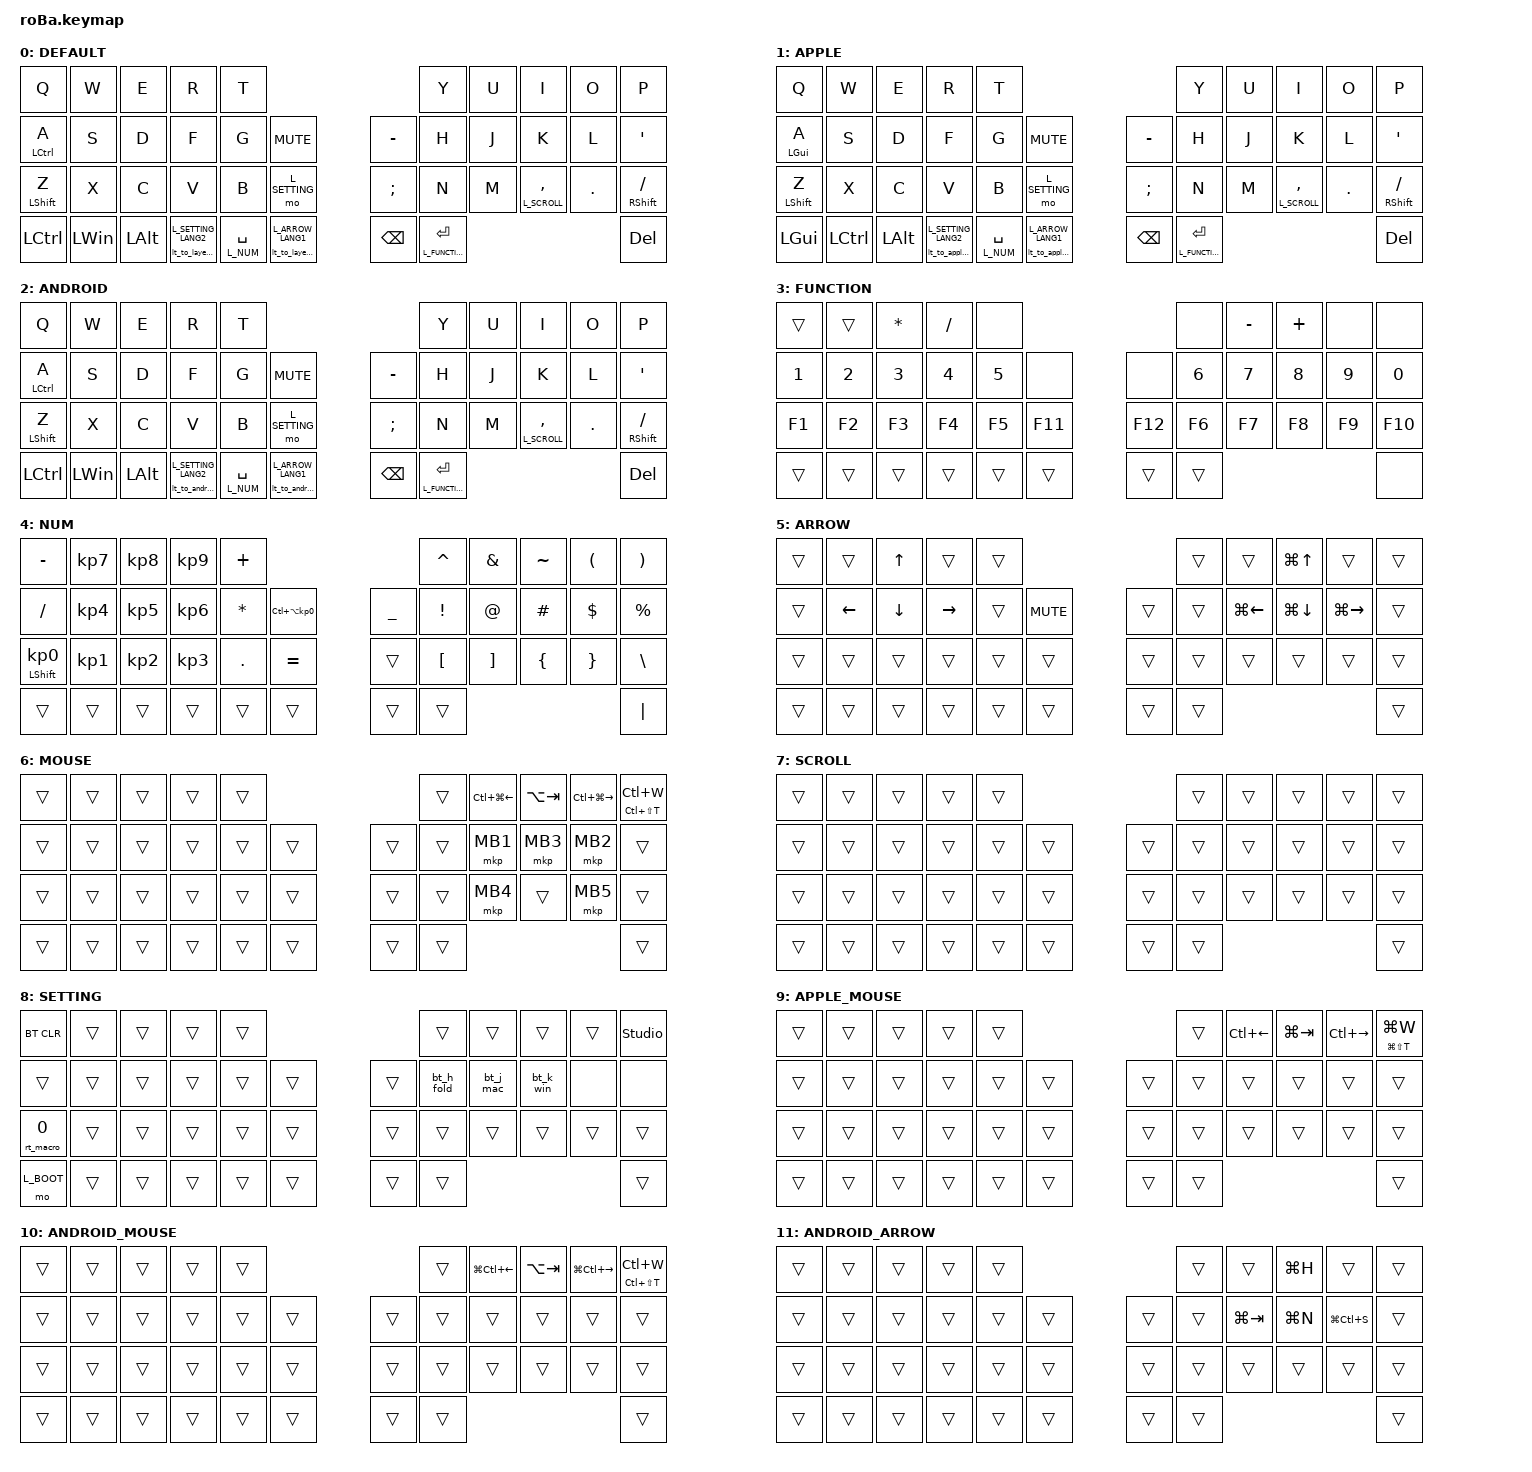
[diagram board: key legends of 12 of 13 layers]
#include <behaviors.dtsi>
#include <dt-bindings/zmk/bt.h>
#include <dt-bindings/zmk/keys.h>
#include <dt-bindings/zmk/pointing.h>
#include <behaviors/runtime-sensor-rotate.dtsi>

#undef ZMK_POINTING_DEFAULT_SCRL_VAL

#define ZMK_POINTING_DEFAULT_SCRL_VAL 80

// Base layers (DEFAULT/APPLE/ANDROID) MUST stay at the lowest indices: ZMK
// resolves a key from the highest active layer, so a base layer numbered
// above SETTING/MOUSE/etc. shadows every momentary layer (bug seen 2026-09-07).
#define L_DEFAULT       0
#define L_APPLE         1
#define L_ANDROID       2
#define L_FUNCTION      3
#define L_NUM           4
#define L_ARROW         5
#define L_MOUSE         6
#define L_SCROLL        7
#define L_SETTING       8
#define L_APPLEMOUSE    9
#define L_ANDROID_MOUSE 10
#define L_ANDROID_ARROW 11
#define L_BOOT          12   // momentary-only; &bootloader chords, everything else &none

&mt {
    flavor = "balanced";
    quick-tap-ms = <0>;
};

&trackball {
    automouse-layer = <L_MOUSE>;
    scroll-layers = <L_SCROLL>;

    // arrows {
    //     layers = <3>;
    //     bindings =
    //         <&kp RIGHT_ARROW>,
    //         <&kp LEFT_ARROW>,
    //         <&kp UP_ARROW>,
    //         <&kp DOWN_ARROW>;
    //     tick = <10>;
    //     wait-ms = <5>;
    //     tap-ms = <5>;
    // };
};

/ {
    combos {
        compatible = "zmk,runtime-combos";

        tab {
            bindings = <&kp TAB>;
            key-positions = <11 10>;
        };

        esc {
            bindings = <&kp ESCAPE>;
            key-positions = <0 1>;
        };

        backspace {
            bindings = <&kp BACKSPACE>;
            key-positions = <9 8>;
        };

        delete {
            bindings = <&kp DELETE>;
            key-positions = <20 21>;
        };

        redo_win {
            bindings = <&kp LC(LS(Z))>;
            key-positions = <22 23 24>;
            layers = <L_DEFAULT L_MOUSE L_ANDROID L_ANDROID_MOUSE>;
        };

        redo_apple {
            bindings = <&kp LG(LS(Z))>;
            key-positions = <22 23 24>;
            layers = <L_APPLE L_APPLEMOUSE>;
        };

        // ; + Del + P (all right hand, 3 keys at once) = UF2 bootloader on the
        // RIGHT half. Combos run on the central (right), which is what we want.
        // Left-half bootloader is the layer chord SETTING + Ctrl + Q (see BOOT).
        bootloader_right {
            bindings = <&bootloader>;
            key-positions = <28 42 9>;
        };
    };

    macros {
        to_layer_0: to_layer_0 {
            compatible = "zmk,behavior-macro-one-param";
            #binding-cells = <1>;
            bindings = <&to L_DEFAULT &macro_param_1to1 &kp MACRO_PLACEHOLDER>;
            label = "TO_LAYER_0";
        };

        to_apple_default: to_apple_default {
            compatible = "zmk,behavior-macro-one-param";
            #binding-cells = <1>;
            bindings = <&to L_APPLE &macro_param_1to1 &kp MACRO_PLACEHOLDER>;
            label = "TO_APPLE_DEFAULT";
        };

        to_android: to_android {
            compatible = "zmk,behavior-macro-one-param";
            #binding-cells = <1>;
            bindings = <&to L_ANDROID &macro_param_1to1 &kp MACRO_PLACEHOLDER>;
            label = "TO_ANDROID";
        };

        // BT profile -> base-layer routing (SETTING layer, right home row).
        // H = Galaxy Z Fold 8 (profile 3, kept from the former SQT slot so the
        // existing bond survives), J = Mac mini (0), K = office Windows (1).
        // L / SQT are intentionally empty (&none). Profiles 2/4 are unused.
        bt_h_fold: bt_h_fold {
            compatible = "zmk,behavior-macro";
            #binding-cells = <0>;
            bindings = <&bt BT_SEL 3 &to L_ANDROID>;
            label = "BT_H_FOLD";
        };

        bt_j_mac: bt_j_mac {
            compatible = "zmk,behavior-macro";
            #binding-cells = <0>;
            bindings = <&bt BT_SEL 0 &to L_APPLE>;
            label = "BT_J_MAC";
        };

        bt_k_win: bt_k_win {
            compatible = "zmk,behavior-macro";
            #binding-cells = <0>;
            bindings = <&bt BT_SEL 1 &to L_DEFAULT>;
            label = "BT_K_WIN";
        };
    };

    behaviors {
        rt_macro: rt_macro {
            compatible = "zmk,behavior-runtime-macro";
            #binding-cells = <1>;
        };

        lt_to_layer_0: lt_to_layer_0 {
            compatible = "zmk,behavior-runtime-hold-tap";
            label = "LAYER_TAP_TO_0";
            bindings = <&mo>, <&to_layer_0>;

            #binding-cells = <2>;
            tapping-term-ms = <200>;
        };

        lt_to_apple_default: lt_to_apple_default {
            compatible = "zmk,behavior-runtime-hold-tap";
            label = "LAYER_TAP_TO_APPLE";
            bindings = <&mo>, <&to_apple_default>;

            #binding-cells = <2>;
            tapping-term-ms = <200>;
        };

        lt_to_android: lt_to_android {
            compatible = "zmk,behavior-runtime-hold-tap";
            label = "LAYER_TAP_TO_ANDROID";
            bindings = <&mo>, <&to_android>;

            #binding-cells = <2>;
            tapping-term-ms = <200>;
        };

        encoder_msc_down_up: encoder_msc_down_up {
            compatible = "zmk,behavior-sensor-rotate";
            label = "ENCODER_MSC_DOWN_UP";
            #sensor-binding-cells = <0>;
            bindings = <&msc SCRL_UP>, <&msc SCRL_DOWN>;

            tap-ms = <50>;
        };

        encoder_vol_down_up: encoder_vol_down_up {
            compatible = "zmk,behavior-runtime-sensor-rotate";
            label = "ENCODER_VOL_DOWN_UP";
            #sensor-binding-cells = <0>;
            cw-binding = <&kp C_VOLUME_DOWN>;
            ccw-binding = <&kp C_VOLUME_UP>;

            tap-ms = <20>;
        };
    };

    conditional_layers {
        compatible = "zmk,runtime-conditional-layers";

        apple_mouse {
            if-layers = <L_APPLE L_MOUSE>;
            then-layer = <L_APPLEMOUSE>;
        };

        android_mouse {
            if-layers = <L_ANDROID L_MOUSE>;
            then-layer = <L_ANDROID_MOUSE>;
        };

        android_arrow {
            if-layers = <L_ANDROID L_ARROW>;
            then-layer = <L_ANDROID_ARROW>;
        };
    };

    keymap {
        compatible = "zmk,keymap";

        DEFAULT {
            bindings = <
&kp Q               &kp W         &kp E         &kp R                        &kp T                                                            &kp Y        &kp U  &kp I               &kp O    &kp P
&mt LEFT_CONTROL A  &kp S         &kp D         &kp F                        &kp G        &kp K_MUTE                           &kp MINUS      &kp H        &kp J  &kp K               &kp L    &kp SQT
&mt LEFT_SHIFT Z    &kp X         &kp C         &kp V                        &kp B        &mo L_SETTING                        &kp SEMICOLON  &kp N        &kp M  &lt L_SCROLL COMMA  &kp DOT  &mt RIGHT_SHIFT SLASH
&kp LCTRL           &kp LEFT_WIN  &kp LEFT_ALT  &lt_to_layer_0 L_SETTING LANG2  &lt L_NUM SPACE  &lt_to_layer_0 L_ARROW LANG1      &kp BACKSPACE  &lt L_FUNCTION ENTER                               &kp DEL
            >;

            sensor-bindings = <&encoder_vol_down_up>;
        };

        APPLE {
            bindings = <
&kp Q             &kp W         &kp E         &kp R                                 &kp T                                                                     &kp Y        &kp U  &kp I               &kp O    &kp P
&mt LEFT_GUI A    &kp S         &kp D         &kp F                                 &kp G        &kp K_MUTE                                    &kp MINUS      &kp H        &kp J  &kp K               &kp L    &kp SQT
&mt LEFT_SHIFT Z  &kp X         &kp C         &kp V                                 &kp B        &mo L_SETTING                                 &kp SEMICOLON  &kp N        &kp M  &lt L_SCROLL COMMA  &kp DOT  &mt RIGHT_SHIFT SLASH
&kp LEFT_GUI      &kp LCTRL     &kp LEFT_ALT  &lt_to_apple_default L_SETTING LANG2  &lt L_NUM SPACE  &lt_to_apple_default L_ARROW LANG1      &kp BACKSPACE  &lt L_FUNCTION ENTER                               &kp DEL
            >;

            sensor-bindings = <&encoder_vol_down_up>;
        };

        // Android (Galaxy Z Fold 8). Meta = LEFT_GUI. Same Ctrl-based base as
        // DEFAULT(Win); only the hold-tap &to target differs so the
        // conditional layers below can key off L_ANDROID.
        ANDROID {
            bindings = <
&kp Q               &kp W         &kp E         &kp R                           &kp T                                                               &kp Y        &kp U  &kp I               &kp O    &kp P
&mt LEFT_CONTROL A  &kp S         &kp D         &kp F                           &kp G        &kp K_MUTE                              &kp MINUS      &kp H        &kp J  &kp K               &kp L    &kp SQT
&mt LEFT_SHIFT Z    &kp X         &kp C         &kp V                           &kp B        &mo L_SETTING                           &kp SEMICOLON  &kp N        &kp M  &lt L_SCROLL COMMA  &kp DOT  &mt RIGHT_SHIFT SLASH
&kp LCTRL           &kp LEFT_WIN  &kp LEFT_ALT  &lt_to_android L_SETTING LANG2  &lt L_NUM SPACE  &lt_to_android L_ARROW LANG1      &kp BACKSPACE  &lt L_FUNCTION ENTER                               &kp DEL
            >;

            sensor-bindings = <&encoder_vol_down_up>;
        };

        FUNCTION {
            bindings = <
&trans        &trans        &kp ASTERISK  &kp SLASH     &none                               &none         &kp MINUS     &kp PLUS      &none         &none
&kp NUMBER_1  &kp NUMBER_2  &kp NUMBER_3  &kp NUMBER_4  &kp NUMBER_5  &none        &none    &kp NUMBER_6  &kp NUMBER_7  &kp NUMBER_8  &kp NUMBER_9  &kp NUMBER_0
&kp F1        &kp F2        &kp F3        &kp F4        &kp F5        &kp F11      &kp F12  &kp F6        &kp F7        &kp F8        &kp F9        &kp F10
&trans        &trans        &trans        &trans        &trans        &trans       &trans   &trans                                                  &none
            >;
        };

        NUM {
            bindings = <
&kp MINUS                   &kp KP_NUMBER_7  &kp KP_NUMBER_8  &kp KP_NUMBER_9  &kp PLUS                                                   &kp CARET         &kp AMPERSAND      &kp TILDE       &kp LEFT_PARENTHESIS  &kp RIGHT_PARENTHESIS
&kp SLASH                   &kp KP_NUMBER_4  &kp KP_NUMBER_5  &kp KP_NUMBER_6  &kp ASTERISK  &kp LC(LA(KP_NUMBER_0))      &kp UNDERSCORE  &kp EXCLAMATION   &kp AT_SIGN        &kp HASH        &kp DOLLAR            &kp PERCENT
&mt LEFT_SHIFT KP_NUMBER_0  &kp KP_NUMBER_1  &kp KP_NUMBER_2  &kp KP_NUMBER_3  &kp PERIOD    &kp EQUAL                    &trans          &kp LEFT_BRACKET  &kp RIGHT_BRACKET  &kp LEFT_BRACE  &kp RIGHT_BRACE       &kp BACKSLASH
&trans                      &trans           &trans           &trans           &trans        &trans                       &trans          &trans                                                                     &kp PIPE
            >;
        };

        ARROW {
            bindings = <
&trans  &trans          &kp UP_ARROW    &trans           &trans                          &trans  &trans        &kp LG(UP)    &trans         &trans
&trans  &kp LEFT_ARROW  &kp DOWN_ARROW  &kp RIGHT_ARROW  &trans  &kp C_MUTE      &trans  &trans  &kp LG(LEFT)  &kp LG(DOWN)  &kp LG(RIGHT)  &trans
&trans  &trans          &trans          &trans           &trans  &trans          &trans  &trans  &trans        &trans        &trans         &trans
&trans  &trans          &trans          &trans           &trans  &trans          &trans  &trans                                             &trans
            >;

            sensor-bindings = <&encoder_vol_down_up>;
        };

        MOUSE {
            bindings = <
&trans  &trans  &trans  &trans  &trans                      &trans  &kp LC(LG(LEFT))  &kp LA(TAB)  &kp LC(LG(RIGHT))  &mt LC(LS(T)) LC(W)
&trans  &trans  &trans  &trans  &trans  &trans      &trans  &trans  &mkp MB1          &mkp MB3   &mkp MB2           &trans
&trans  &trans  &trans  &trans  &trans  &trans      &trans  &trans  &mkp MB4          &trans     &mkp MB5           &trans
&trans  &trans  &trans  &trans  &trans  &trans      &trans  &trans                                                  &trans
            >;
        };

        SCROLL {
            bindings = <
&trans  &trans  &trans  &trans  &trans                      &trans  &trans  &trans  &trans  &trans
&trans  &trans  &trans  &trans  &trans  &trans      &trans  &trans  &trans  &trans  &trans  &trans
&trans  &trans  &trans  &trans  &trans  &trans      &trans  &trans  &trans  &trans  &trans  &trans
&trans  &trans  &trans  &trans  &trans  &trans      &trans  &trans                          &trans
            >;
        };

        // SETTING + Ctrl (bottom-left) enters the BOOT layer; BOOT + Q = &bootloader
        // on the LEFT half (reset-type behaviors run on the half that produced the
        // key event). Three left-hand keys at once, no reset button needed.
        SETTING {
            bindings = <
&bt BT_CLR  &trans  &trans  &trans  &trans                      &trans          &trans        &trans        &trans      &studio_unlock
&trans      &trans  &trans  &trans  &trans  &trans      &trans  &bt_h_fold     &bt_j_mac     &bt_k_win     &none       &none
&rt_macro 0  &trans  &trans  &trans  &trans  &trans      &trans  &trans         &trans        &trans        &trans      &trans
&mo L_BOOT  &trans  &trans  &trans  &trans  &trans      &trans  &trans                                                 &trans
            >;
        };

        APPLE_MOUSE {
            bindings = <
&trans  &trans  &trans  &trans  &trans                      &trans  &kp LC(LEFT)  &kp LG(TAB)  &kp LC(RIGHT)  &mt LG(LS(T)) LG(W)
&trans  &trans  &trans  &trans  &trans  &trans      &trans  &trans  &trans        &trans  &trans         &trans
&trans  &trans  &trans  &trans  &trans  &trans      &trans  &trans  &trans        &trans  &trans         &trans
&trans  &trans  &trans  &trans  &trans  &trans      &trans  &trans                                      &trans
            >;
        };

        // U/O = split-screen left/right (Meta+Ctrl+Left/Right), I = app switch
        // (Alt+Tab), P = reopen/close tab. Positionally matches MOUSE/APPLE_MOUSE.
        ANDROID_MOUSE {
            bindings = <
&trans  &trans  &trans  &trans  &trans                      &trans  &kp LG(LC(LEFT))  &kp LA(TAB)  &kp LG(LC(RIGHT))  &mt LC(LS(T)) LC(W)
&trans  &trans  &trans  &trans  &trans  &trans      &trans  &trans  &trans            &trans       &trans             &trans
&trans  &trans  &trans  &trans  &trans  &trans      &trans  &trans  &trans            &trans       &trans             &trans
&trans  &trans  &trans  &trans  &trans  &trans      &trans  &trans                                                    &trans
            >;
        };

        // I = home (Meta+H), J = recents (Meta+Tab), K = notification shade (Meta+N),
        // L = screenshot (Meta+Ctrl+S).
        ANDROID_ARROW {
            bindings = <
&trans  &trans  &trans  &trans  &trans                      &trans  &trans       &kp LG(H)  &trans         &trans
&trans  &trans  &trans  &trans  &trans  &trans      &trans  &trans  &kp LG(TAB)  &kp LG(N)  &kp LG(LC(S))  &trans
&trans  &trans  &trans  &trans  &trans  &trans      &trans  &trans  &trans       &trans     &trans         &trans
&trans  &trans  &trans  &trans  &trans  &trans      &trans  &trans                                         &trans
            >;
        };

        // Reached only via SETTING + Ctrl. Q = bootloader on the LEFT half; every
        // other key is &none so nothing else can fire while the chord is held.
        BOOT {
            bindings = <
&bootloader  &none  &none  &none  &none                    &none  &none  &none  &none  &none
&none        &none  &none  &none  &none  &none      &none  &none  &none  &none  &none  &none
&none        &none  &none  &none  &none  &none      &none  &none  &none  &none  &none  &none
&none        &none  &none  &none  &none  &none      &none  &none                       &none
            >;
        };

    };
};
